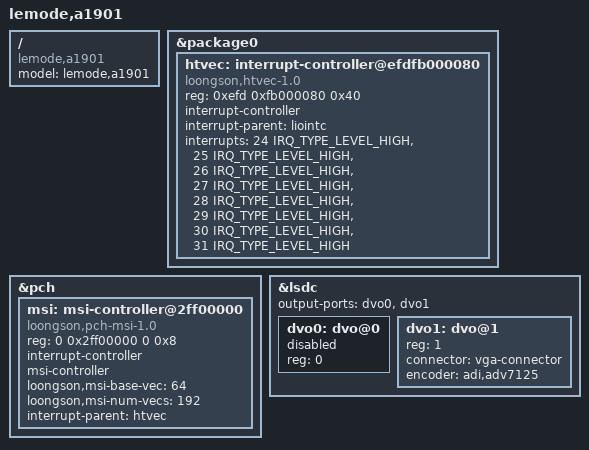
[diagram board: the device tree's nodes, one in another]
// SPDX-License-Identifier: GPL-2.0

/dts-v1/;

#include "loongson64g-package.dtsi"
#include "ls7a-pch.dtsi"

/ {
	compatible = "lemode,a1901", "loongson,loongson64g-4core-ls7a";
	model = "lemode,a1901";
};

&package0 {
	htvec: interrupt-controller@efdfb000080 {
		compatible = "loongson,htvec-1.0";
		reg = <0xefd 0xfb000080 0x40>;
		interrupt-controller;
		#interrupt-cells = <1>;

		interrupt-parent = <&liointc>;
		interrupts = <24 IRQ_TYPE_LEVEL_HIGH>,
			     <25 IRQ_TYPE_LEVEL_HIGH>,
			     <26 IRQ_TYPE_LEVEL_HIGH>,
			     <27 IRQ_TYPE_LEVEL_HIGH>,
			     <28 IRQ_TYPE_LEVEL_HIGH>,
			     <29 IRQ_TYPE_LEVEL_HIGH>,
			     <30 IRQ_TYPE_LEVEL_HIGH>,
			     <31 IRQ_TYPE_LEVEL_HIGH>;
	};
};

&pch {
	msi: msi-controller@2ff00000 {
		compatible = "loongson,pch-msi-1.0";
		reg = <0 0x2ff00000 0 0x8>;
		interrupt-controller;
		msi-controller;
		loongson,msi-base-vec = <64>;
		loongson,msi-num-vecs = <192>;
		interrupt-parent = <&htvec>;
	};
};

&lsdc {
	/* use_vram_helper; */
	output-ports = <&dvo0 &dvo1>;

	#address-cells = <1>;
	#size-cells = <0>;

	dvo0: dvo@0 {
		/* 0 for DVO0 */
		reg = <0>;
		status = "disabled";
	};

	dvo1: dvo@1 {
		/* 1 for DVO1 */
		reg = <1>;
		connector = "vga-connector";
		encoder = "adi,adv7125";
		status = "okay";
	};
};
